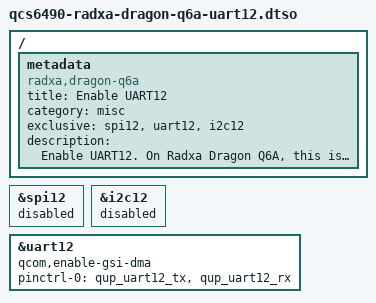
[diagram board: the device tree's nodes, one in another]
// SPDX-License-Identifier: BSD-3-Clause
/*
 * Copyright (c) 2025 Radxa Computer (Shenzhen) Co., Ltd.
 */

/dts-v1/;
/plugin/;

/ {
    metadata {
        title = "Enable UART12";
        compatible = "radxa,dragon-q6a";
        category = "misc";
        exclusive = "spi12", "uart12", "i2c12";
        description = "Enable UART12. 
On Radxa Dragon Q6A, this is pin 23(tx), 24(rx).";
    };
};

&spi12 {
	status = "disabled";
};

&i2c12 {
	status = "disabled";
};

&uart12 {
	qcom,enable-gsi-dma;
	status = "okay";
    pinctrl-0 = <&qup_uart12_tx>, <&qup_uart12_rx>;
};
